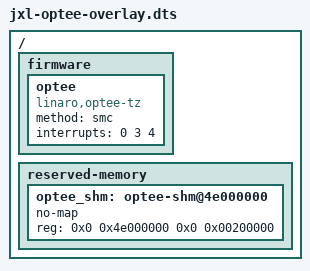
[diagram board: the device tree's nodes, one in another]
/*
 * Linux DTB overlay that adds the OP-TEE firmware node so the Linux optee
 * driver binds. Applied on top of jxl-linux.dtb (or jxl-xen.dtb) only by
 * the jxl-optee / jxl-xen-optee start.sh modes, so the base DTB used by
 * non-OP-TEE chains (jxl-linux, jxl-xen, jxl-xen-atf, ...) stays untouched.
 */

/dts-v1/;
/plugin/;

/ {
	fragment@0 {
		target-path = "/";

		__overlay__ {
			firmware {
				optee {
					compatible = "linaro,optee-tz";
					method = "smc";
					/*
					 * OP-TEE async notification IRQ. Must match
					 * CFG_CORE_ASYNC_NOTIF_GIC_INTID in
					 * core/arch/arm/plat-vexpress/conf.mk (35 = SPI 3).
					 */
					interrupts = <0 3 4>;
				};
			};

			reserved-memory {
				#address-cells = <2>;
				#size-cells = <2>;
				ranges;

				/*
				 * Carve OP-TEE's NS shared memory window
				 * (CFG_SHMEM_START / CFG_SHMEM_SIZE) out of the
				 * kernel's view. `no-map` keeps the kernel from
				 * adding it to the linear map, so the optee
				 * driver's memremap can land it as cached RW
				 * without aliasing kernel rodata.
				 */
				optee_shm: optee-shm@4e000000 {
					no-map;
					reg = <0x0 0x4e000000 0x0 0x00200000>;
				};
			};
		};
	};
};
